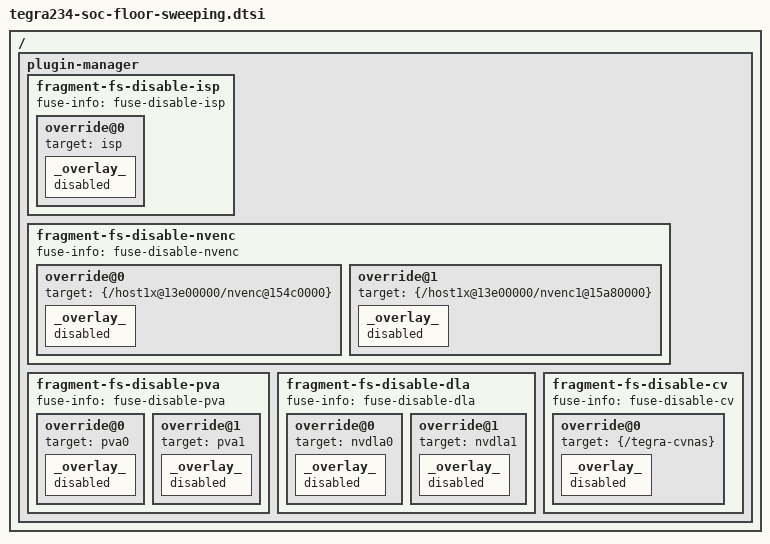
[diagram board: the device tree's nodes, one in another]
/*
 * Copyright (c) 2018-2020, NVIDIA CORPORATION.  All rights reserved.
 *
 * This program is free software; you can redistribute it and/or modify it
 * under the terms and conditions of the GNU General Public License,
 * version 2, as published by the Free Software Foundation.
 *
 * This program is distributed in the hope it will be useful, but WITHOUT
 * ANY WARRANTY; without even the implied warranty of MERCHANTABILITY or
 * FITNESS FOR A PARTICULAR PURPOSE.  See the GNU General Public License for
 * more details.
 *
 * You should have received a copy of the GNU General Public License
 * along with this program.  If not, see <http://www.gnu.org/licenses/>.
 */

/*
 * tegra234-soc-floor-sweeping.dtsi: Plugin manager file for floorsweeping devices
 */

/ {
	plugin-manager {
		fragment-fs-disable-isp {
			fuse-info = "fuse-disable-isp";
			override@0 {
				target = <&isp>;
				_overlay_ {
					status = "disabled";
				};
			};
		};

		fragment-fs-disable-nvenc {
			fuse-info = "fuse-disable-nvenc";
			override@0 {
				target = <&{/host1x@13e00000/nvenc@154c0000}>;
				_overlay_ {
					status = "disabled";
				};
			};

			override@1 {
				target = <&{/host1x@13e00000/nvenc1@15a80000}>;
				_overlay_ {
					status = "disabled";
				};
			};
		};

		fragment-fs-disable-pva {
			fuse-info = "fuse-disable-pva";
			override@0 {
				target = <&pva0>;
				_overlay_ {
					status = "disabled";
				};
			};

			override@1 {
				target = <&pva1>;
				_overlay_ {
					status = "disabled";
				};
			};
		};

		fragment-fs-disable-dla {
			fuse-info = "fuse-disable-dla";
			override@0 {
				target = <&nvdla0>;
				_overlay_ {
					status = "disabled";
				};
			};

			override@1 {
				target = <&nvdla1>;
				_overlay_ {
					status = "disabled";
				};
			};
		};

		fragment-fs-disable-cv {
			fuse-info = "fuse-disable-cv";
			override@0 {
				target = <&{/tegra-cvnas}>;
				_overlay_ {
					status = "disabled";
				};
			};
		};
	};
};
